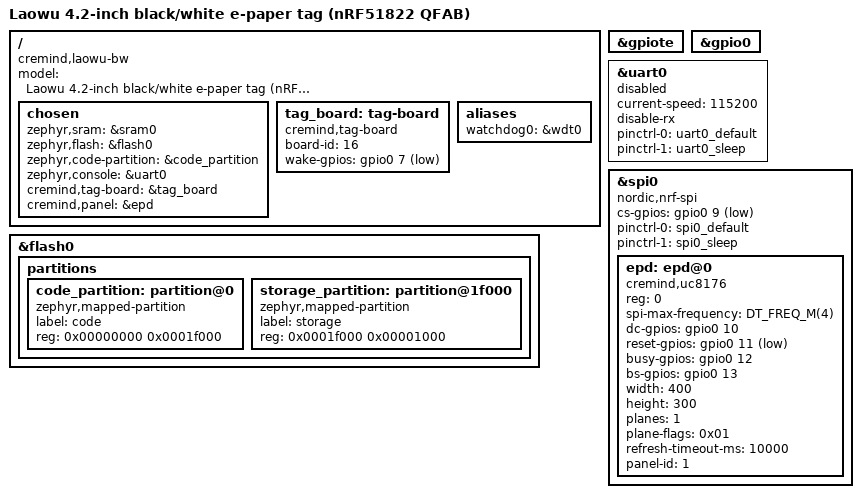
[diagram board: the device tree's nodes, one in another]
/*
 * Copyright (c) 2026 Cremind
 * SPDX-License-Identifier: MIT
 *
 * Laowu 4.2-inch black/white e-paper tag: nRF51822 QFAB (128 KiB flash,
 * 16 KiB SRAM), UltraChip UC8176 400x300 panel. Pins from hardware/matrix.yaml
 * (source: EPD-nRF5 docs/devices.md hardware documentation). Nothing here has
 * been verified on a physical sample yet (docs/hardware/verification.md).
 */

/dts-v1/;
#include <nordic/nrf51822_qfab.dtsi>
#include "laowu_bw-pinctrl.dtsi"

/ {
	model = "Laowu 4.2-inch black/white e-paper tag (nRF51822 QFAB)";
	compatible = "cremind,laowu-bw";

	chosen {
		zephyr,sram = &sram0;
		zephyr,flash = &flash0;
		zephyr,code-partition = &code_partition;
		/* Only takes effect when a debug overlay enables uart0. */
		zephyr,console = &uart0;
		cremind,tag-board = &tag_board;
		cremind,panel = &epd;
	};

	tag_board: tag-board {
		compatible = "cremind,tag-board";
		board-id = <16>;
		/* Wake source and polarity unverified: firmware must not rely on it. */
		wake-gpios = <&gpio0 7 (GPIO_PULL_UP | GPIO_ACTIVE_LOW)>;
	};

	/* LEDs unconfirmed on this board: none defined. */

	aliases {
		watchdog0 = &wdt0;
	};
};

&gpiote {
	status = "okay";
};

&gpio0 {
	status = "okay";
};

/* Debug TX pad only (P0.06). Enable in an overlay for bring-up. */
&uart0 {
	status = "disabled";
	current-speed = <115200>;
	disable-rx;
	pinctrl-0 = <&uart0_default>;
	pinctrl-1 = <&uart0_sleep>;
	pinctrl-names = "default", "sleep";
};

&spi0 {
	compatible = "nordic,nrf-spi";
	status = "okay";
	cs-gpios = <&gpio0 9 GPIO_ACTIVE_LOW>;
	pinctrl-0 = <&spi0_default>;
	pinctrl-1 = <&spi0_sleep>;
	pinctrl-names = "default", "sleep";

	epd: epd@0 {
		compatible = "cremind,uc8176";
		reg = <0>;
		spi-max-frequency = <DT_FREQ_M(4)>;
		dc-gpios = <&gpio0 10 GPIO_ACTIVE_HIGH>;
		reset-gpios = <&gpio0 11 GPIO_ACTIVE_LOW>;
		busy-gpios = <&gpio0 12 GPIO_ACTIVE_HIGH>;
		bs-gpios = <&gpio0 13 GPIO_ACTIVE_HIGH>;
		width = <400>;
		height = <300>;
		planes = <1>;
		/* Plane polarity to be confirmed during panel verification. */
		plane-flags = <0x01>;
		/* Upper bound until measured during qualification. */
		refresh-timeout-ms = <10000>;
		panel-id = <1>;	/* UC8176_420_BW */
	};
};

&flash0 {
	partitions {
		ranges;
		#address-cells = <1>;
		#size-cells = <1>;

		code_partition: partition@0 {
			compatible = "zephyr,mapped-partition";
			label = "code";
			reg = <0x00000000 0x0001f000>;
		};

		/* NVS: 4 x 1 KiB pages at the end of flash (docs/firmware-notes.md section 9). */
		storage_partition: partition@1f000 {
			compatible = "zephyr,mapped-partition";
			label = "storage";
			reg = <0x0001f000 0x00001000>;
		};
	};
};
